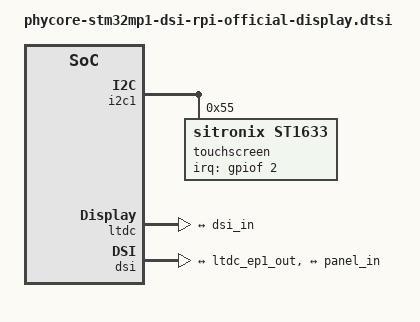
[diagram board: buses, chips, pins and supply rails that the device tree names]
// SPDX-License-Identifier: (GPL-2.0+ OR BSD-3-Clause)
/*
 * Copyright (C) PHYTEC GmbH 2019 - All Rights Reserved
 * Author: Dom VOVARD <dom.vovard@linrt.com>.
 */


&i2c1 {
        status = "okay";

        touchscreen@55 {
                compatible = "sitronix,st1633";
                reg = <0x55>;
                interrupts = <2 2>;
                interrupt-parent = <&gpiof>;
                interrupt-controller;
                status = "okay";
        };
};

&ltdc {
        dma-ranges;
        status = "okay";

        port {
                #address-cells = <1>;
                #size-cells = <0>;

                ltdc_ep1_out: endpoint@1 {
                        reg = <1>;
                        remote-endpoint = <&dsi_in>;
                };
        };
};

&dsi {
        #address-cells = <1>;
        #size-cells = <0>;
        status = "okay";

        ports {
                #address-cells = <1>;
                #size-cells = <0>;

                port@0 {
                        reg = <0>;
                        dsi_in: endpoint {
                                remote-endpoint = <&ltdc_ep1_out>;
                        };
                };

                port@1 {
                        reg = <1>;
                        dsi_out: endpoint {
                                remote-endpoint = <&panel_in>;
                        };
                };
        };
};
